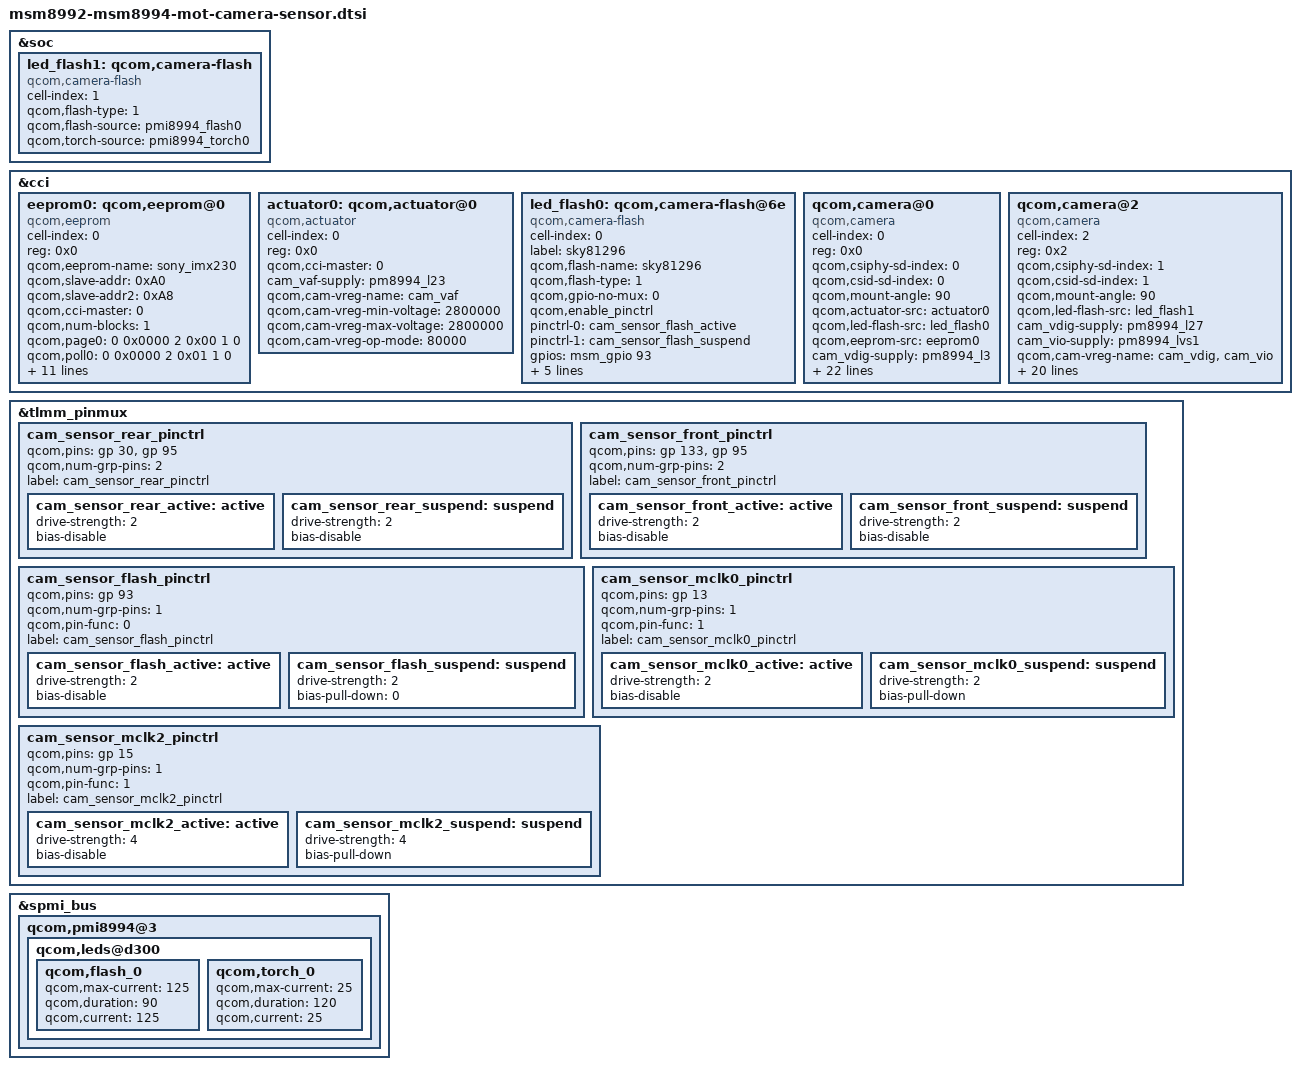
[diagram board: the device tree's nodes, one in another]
/*
 * Copyright (c) 2014, The Linux Foundation. All rights reserved.
 *
 * This program is free software; you can redistribute it and/or modify
 * it under the terms of the GNU General Public License version 2 and
 * only version 2 as published by the Free Software Foundation.
 *
 * This program is distributed in the hope that it will be useful,
 * but WITHOUT ANY WARRANTY; without even the implied warranty of
 * MERCHANTABILITY or FITNESS FOR A PARTICULAR PURPOSE.  See the
 * GNU General Public License for more details.
 */

&soc {
	led_flash1: qcom,camera-flash {
		cell-index = <1>;
		compatible = "qcom,camera-flash";
		qcom,flash-type = <1>;
		qcom,flash-source = <&pmi8994_flash0>;
		qcom,torch-source = <&pmi8994_torch0>;
	};
};

&cci {

	/* IMX230 EEPROM */
	eeprom0: qcom,eeprom@0 {
		cell-index = <0>;
		reg = <0x0>;
		qcom,eeprom-name = "sony_imx230";
		compatible = "qcom,eeprom";
		qcom,slave-addr = <0xA0>;
		qcom,slave-addr2 = <0xA8>;
		qcom,cci-master = <0>;
		qcom,num-blocks = <1>;
		qcom,page0 = <0 0x0000 2 0x00 1 0>;
		qcom,poll0 = <0 0x0000 2 0x01 1 0>;
		qcom,mem0 = <8192 0x0000 2 0 1 0>;

		cam_vio-supply = <&pm8994_lvs1>;
		qcom,cam-vreg-name = "cam_vio";
		qcom,cam-vreg-min-voltage = <0>;
		qcom,cam-vreg-max-voltage = <0>;
		qcom,cam-vreg-op-mode = <0>;
		qcom,gpio-no-mux = <0>;

		qcom,cam-power-seq-type = "sensor_vreg";
		qcom,cam-power-seq-val = "cam_vio";
		qcom,cam-power-seq-cfg-val = <1>;
		qcom,cam-power-seq-delay = <3>;

		status = "ok";
	};

	/* IMX230 Actuator */
	actuator0: qcom,actuator@0 {
		cell-index = <0>;
		reg = <0x0>;
		compatible = "qcom,actuator";
		qcom,cci-master = <0>;
		cam_vaf-supply = <&pm8994_l23>;
		qcom,cam-vreg-name = "cam_vaf";
		qcom,cam-vreg-min-voltage = <2800000>;
		qcom,cam-vreg-max-voltage = <2800000>;
		qcom,cam-vreg-op-mode = <80000>;
	};

	/* skywork81296 */
	led_flash0: qcom,camera-flash@6e {
		cell-index = <0>;
		compatible = "qcom,camera-flash";
		label = "sky81296";
		qcom,flash-name = "sky81296";
		qcom,flash-type = <1>;
		qcom,gpio-no-mux = <0>;
		qcom,enable_pinctrl;
		pinctrl-names = "cam_default", "cam_suspend";
		pinctrl-0 = <&cam_sensor_flash_active>;
		pinctrl-1 = <&cam_sensor_flash_suspend>;
		gpios = <&msm_gpio 93 0>;
		qcom,gpio-flash-en = <0>;
		qcom,gpio-req-tbl-num = <0 >;
		qcom,gpio-req-tbl-flags = <0>;
		qcom,gpio-req-tbl-label = "FLASH_EN";
		qcom,cci-master = <0>;
	};

	/* IMX230 */
	qcom,camera@0 {
		cell-index = <0>;
		compatible = "qcom,camera";
		reg = <0x0>;
		qcom,csiphy-sd-index = <0>;
		qcom,csid-sd-index = <0>;
		qcom,mount-angle = <90>;
		qcom,actuator-src = <&actuator0>;
		qcom,led-flash-src = <&led_flash0>;
		qcom,eeprom-src = <&eeprom0>;
		cam_vdig-supply = <&pm8994_l3>;
		cam_vio-supply = <&pm8994_lvs1>;
		qcom,cam-vreg-name = "cam_vdig", "cam_vio";
		qcom,cam-vreg-min-voltage = <0 0>;
		qcom,cam-vreg-max-voltage = <0 0>;
		qcom,cam-vreg-op-mode = <0 0>;
		qcom,gpio-no-mux = <0>;
		pinctrl-names = "cam_default", "cam_suspend";
		pinctrl-0 = <&cam_sensor_mclk0_active &cam_sensor_rear_active>;
		pinctrl-1 = <&cam_sensor_mclk0_suspend &cam_sensor_rear_suspend>;
		gpios = <&msm_gpio 13 0>,
			<&msm_gpio 30 0>,
			<&msm_gpio 132 0>;
		qcom,gpio-reset = <1>;
		qcom,gpio-vana = <2>;
		qcom,gpio-req-tbl-num = <0 1 2>;
		qcom,gpio-req-tbl-flags = <1 0 0>;
		qcom,gpio-req-tbl-label = "CAMIF_MCLK0",
					  "CAM_RESET0",
					  "CAM_VANA";
		qcom,sensor-position = <0>;
		qcom,sensor-mode = <0>;
		qcom,cci-master = <0>;
		status = "ok";
		clocks = <&clock_mmss clk_mclk0_clk_src>,
				<&clock_mmss clk_camss_mclk0_clk>;
		clock-names = "cam_src_clk", "cam_clk";
	};

	/* ov5693 */
	qcom,camera@2 {
		cell-index = <2>;
		compatible = "qcom,camera";
		reg = <0x2>;
		qcom,csiphy-sd-index = <1>;
		qcom,csid-sd-index = <1>;
		qcom,mount-angle = <90>;
		qcom,led-flash-src = <&led_flash1>;
		cam_vdig-supply = <&pm8994_l27>;
		cam_vio-supply = <&pm8994_lvs1>;
		qcom,cam-vreg-name = "cam_vdig", "cam_vio";
		qcom,cam-vreg-min-voltage = <1050000 0>;
		qcom,cam-vreg-max-voltage = <1050000 0>;
		qcom,cam-vreg-op-mode = <1050000 0>;
		qcom,gpio-no-mux = <0>;
		pinctrl-names = "cam_default", "cam_suspend";
		pinctrl-0 = <&cam_sensor_mclk2_active &cam_sensor_front_active>;
		pinctrl-1 = <&cam_sensor_mclk2_suspend &cam_sensor_front_suspend>;
		gpios = <&msm_gpio 15 0>,
			<&msm_gpio 133 0>,
			<&msm_gpio 95 0>;
		qcom,gpio-reset = <1>;
		qcom,gpio-vana = <2>;
		qcom,gpio-req-tbl-num = <0 1 2>;
		qcom,gpio-req-tbl-flags = <1 0 0>;
		qcom,gpio-req-tbl-label = "CAMIF_MCLK2",
					  "CAM_RESET2",
					  "CAM_VANA";
		qcom,sensor-position = <1>;
		qcom,sensor-mode = <0>;
		qcom,cci-master = <0>;
		status = "ok";
		clocks = <&clock_mmss clk_mclk2_clk_src>,
				<&clock_mmss clk_camss_mclk2_clk>;
		clock-names = "cam_src_clk", "cam_clk";
	};
};

&tlmm_pinmux {
	/delete-node/ cam_sensor_rear_active;
	/delete-node/ cam_sensor_rear_suspend;
	/delete-node/ cam_sensor_front_active;
	/delete-node/ cam_sensor_front_suspend;
	/delete-node/ cam_sensor_mclk0_active;
	/delete-node/ cam_sensor_mclk0_suspend;
	/delete-node/ cam_sensor_mclk2_active;
	/delete-node/ cam_sensor_mclk2_suspend;

	cam_sensor_rear_pinctrl {
		/*RESET, AVDD_EN */
		qcom,pins = <&gp 30>, <&gp 95>;
		qcom,num-grp-pins = <2>;
		label = "cam_sensor_rear_pinctrl";
		/* active state */

		cam_sensor_rear_active: active {
			drive-strength = <2>; /* 2 MA */
			bias-disable; /* No PULL */
		};

		/*suspended state */
		cam_sensor_rear_suspend: suspend {
			drive-strength = <2>; /* 2 MA */
			bias-disable; /* No PULL */
		};
	};

	cam_sensor_front_pinctrl {
		/* RESET, AVDD_EN */
		qcom,pins = <&gp 133>, <&gp 95>;
		qcom,num-grp-pins = <2>;
		label = "cam_sensor_front_pinctrl";

		/* active state */
		cam_sensor_front_active: active {
			drive-strength = <2>; /* 2 MA */
			bias-disable; /* No PULL */
		};

		/*suspended state */
		cam_sensor_front_suspend: suspend {
			drive-strength = <2>; /* 2 MA */
			bias-disable; /* No PULL */
		};
	};

	cam_sensor_flash_pinctrl {
		/* flash */
		qcom,pins = <&gp 93>;
		qcom,num-grp-pins = <1>;
		qcom,pin-func = <0>;
		label = "cam_sensor_flash_pinctrl";

		/* active state */
		cam_sensor_flash_active: active {
			drive-strength = <2>; /* 2 MA */
			bias-disable; /* No PULL */
		};

		/* suspended state */
		cam_sensor_flash_suspend: suspend {
			drive-strength = <2>; /* 2 MA */
			bias-pull-down = <0>; /* PULL DOWN */
		};
	};

	cam_sensor_mclk0_pinctrl {
		/* MCLK0 */
		qcom,pins = <&gp 13>;
		qcom,num-grp-pins = <1>;
		qcom,pin-func = <1>;
		label = "cam_sensor_mclk0_pinctrl";

		/* active state */
		cam_sensor_mclk0_active: active {
			drive-strength = <2>; /* 2 MA */
			bias-disable; /* No PULL */
		};

		/*suspended state */
		cam_sensor_mclk0_suspend: suspend {
			drive-strength = <2>; /* 2 MA */
			bias-pull-down; /* PULL DOWN */
		};
	};

	cam_sensor_mclk2_pinctrl {
		/* MCLK2 */
		qcom,pins = <&gp 15>;
		qcom,num-grp-pins = <1>;
		qcom,pin-func = <1>;
		label = "cam_sensor_mclk2_pinctrl";

		/* active state */
		cam_sensor_mclk2_active: active {
			drive-strength = <4>; /* 4 MA */
			bias-disable; /* No PULL */
		};

		/* suspend state */
		cam_sensor_mclk2_suspend: suspend {
			drive-strength = <4>; /* 4 MA */
			bias-pull-down; /* PULL DOWN */
		};
	};
};

&spmi_bus {
	qcom,pmi8994@3 {
		qcom,leds@d300 {
			qcom,flash_0 {
				qcom,max-current = <125>;
				qcom,duration = <90>;
				qcom,current = <125>;
			};
			qcom,torch_0 {
				qcom,max-current = <25>;
				qcom,duration = <120>;
				qcom,current = <25>;
			};
		};
	};
};
